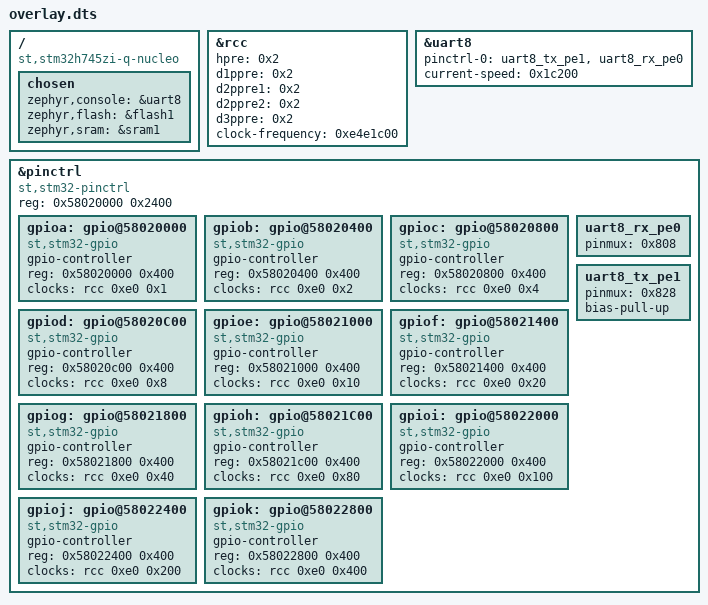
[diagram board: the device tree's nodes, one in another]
/ {
	compatible = "st,stm32h745zi-q-nucleo";
	chosen {
		zephyr,console = &uart8;
		zephyr,flash = &flash1;
		zephyr,sram = &sram1;
	};
};
&rcc{
	hpre = < 0x2 >;
	d1ppre = < 0x2 >;
	d2ppre1 = < 0x2 >;
	d2ppre2 = < 0x2 >;
	d3ppre = < 0x2 >;
	clock-frequency = < 0xe4e1c00 >;
};
&uart8{
	status = "okay";
	pinctrl-0 = < &uart8_tx_pe1 &uart8_rx_pe0 >;
	pinctrl-names = "default";
	current-speed = < 0x1c200 >;
};
&pinctrl{
	compatible = "st,stm32-pinctrl";
	#address-cells = < 0x1 >;
	#size-cells = < 0x1 >;
	reg = < 0x58020000 0x2400 >;
	gpioa: gpio@58020000 {
		compatible = "st,stm32-gpio";
		gpio-controller;
		#gpio-cells = < 0x2 >;
		reg = < 0x58020000 0x400 >;
		clocks = < &rcc 0xe0 0x1 >;
	};
	gpiob: gpio@58020400 {
		compatible = "st,stm32-gpio";
		gpio-controller;
		#gpio-cells = < 0x2 >;
		reg = < 0x58020400 0x400 >;
		clocks = < &rcc 0xe0 0x2 >;
	};
	gpioc: gpio@58020800 {
		compatible = "st,stm32-gpio";
		gpio-controller;
		#gpio-cells = < 0x2 >;
		reg = < 0x58020800 0x400 >;
		clocks = < &rcc 0xe0 0x4 >;
	};
	gpiod: gpio@58020C00 {
		compatible = "st,stm32-gpio";
		gpio-controller;
		#gpio-cells = < 0x2 >;
		reg = < 0x58020c00 0x400 >;
		clocks = < &rcc 0xe0 0x8 >;
	};
	gpioe: gpio@58021000 {
		compatible = "st,stm32-gpio";
		gpio-controller;
		#gpio-cells = < 0x2 >;
		reg = < 0x58021000 0x400 >;
		clocks = < &rcc 0xe0 0x10 >;
	};
	gpiof: gpio@58021400 {
		compatible = "st,stm32-gpio";
		gpio-controller;
		#gpio-cells = < 0x2 >;
		reg = < 0x58021400 0x400 >;
		clocks = < &rcc 0xe0 0x20 >;
	};
	gpiog: gpio@58021800 {
		compatible = "st,stm32-gpio";
		gpio-controller;
		#gpio-cells = < 0x2 >;
		reg = < 0x58021800 0x400 >;
		clocks = < &rcc 0xe0 0x40 >;
	};
	gpioh: gpio@58021C00 {
		compatible = "st,stm32-gpio";
		gpio-controller;
		#gpio-cells = < 0x2 >;
		reg = < 0x58021c00 0x400 >;
		clocks = < &rcc 0xe0 0x80 >;
	};
	gpioi: gpio@58022000 {
		compatible = "st,stm32-gpio";
		gpio-controller;
		#gpio-cells = < 0x2 >;
		reg = < 0x58022000 0x400 >;
		clocks = < &rcc 0xe0 0x100 >;
	};
	gpioj: gpio@58022400 {
		compatible = "st,stm32-gpio";
		gpio-controller;
		#gpio-cells = < 0x2 >;
		reg = < 0x58022400 0x400 >;
		clocks = < &rcc 0xe0 0x200 >;
	};
	gpiok: gpio@58022800 {
		compatible = "st,stm32-gpio";
		gpio-controller;
		#gpio-cells = < 0x2 >;
		reg = < 0x58022800 0x400 >;
		clocks = < &rcc 0xe0 0x400 >;
	};
	uart8_rx_pe0: uart8_rx_pe0 {
		pinmux = < 0x808 >;
	};
	uart8_tx_pe1: uart8_tx_pe1 {
		pinmux = < 0x828 >;
		bias-pull-up;
	};
};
